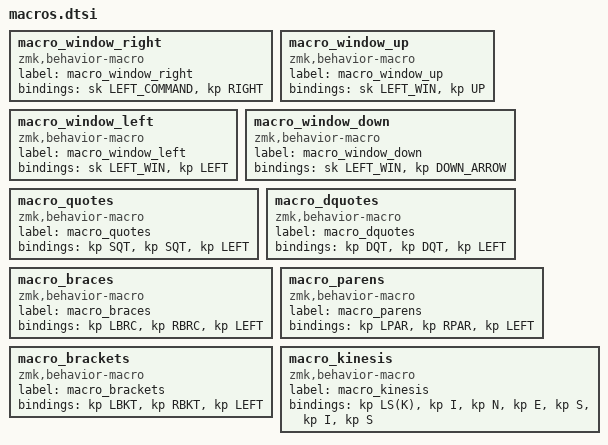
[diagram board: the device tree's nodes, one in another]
macro_window_right: macro_window_right{
compatible = "zmk,behavior-macro";
label = "macro_window_right";
#binding-cells = <0>;
bindings = <&sk LEFT_COMMAND>, <&kp RIGHT>;
};
macro_window_up: macro_window_up{
compatible = "zmk,behavior-macro";
label = "macro_window_up";
#binding-cells = <0>;
bindings = <&sk LEFT_WIN>, <&kp UP>;
};
macro_window_left: macro_window_left{
compatible = "zmk,behavior-macro";
label = "macro_window_left";
#binding-cells = <0>;
bindings = <&sk LEFT_WIN>, <&kp LEFT>;
};
macro_window_down: macro_window_down{
compatible = "zmk,behavior-macro";
label = "macro_window_down";
#binding-cells = <0>;
bindings = <&sk LEFT_WIN>, <&kp DOWN_ARROW>;
};
macro_quotes: macro_quotes{
compatible = "zmk,behavior-macro";
label = "macro_quotes";
#binding-cells = <0>;
bindings = <&kp SQT>, <&kp SQT>, <&kp LEFT>;
};
macro_dquotes: macro_dquotes{
compatible = "zmk,behavior-macro";
label = "macro_dquotes";
#binding-cells = <0>;
bindings = <&kp DQT>, <&kp DQT>, <&kp LEFT>;
};
macro_braces: macro_braces{
compatible = "zmk,behavior-macro";
label = "macro_braces";
#binding-cells = <0>;
bindings = <&kp LBRC>, <&kp RBRC>, <&kp LEFT>;
};
macro_parens: macro_parens{
compatible = "zmk,behavior-macro";
label = "macro_parens";
#binding-cells = <0>;
bindings = <&kp LPAR>, <&kp RPAR>, <&kp LEFT>;
};
macro_brackets: macro_brackets{
compatible = "zmk,behavior-macro";
label = "macro_brackets";
#binding-cells = <0>;
bindings = <&kp LBKT>, <&kp RBKT>, <&kp LEFT>;
};
macro_kinesis: macro_kinesis{
compatible = "zmk,behavior-macro";
label = "macro_kinesis";
#binding-cells = <0>;
bindings = <&kp LS(K)>, <&kp I>, <&kp N>, <&kp E>, <&kp S>, <&kp I>, <&kp S>;
};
